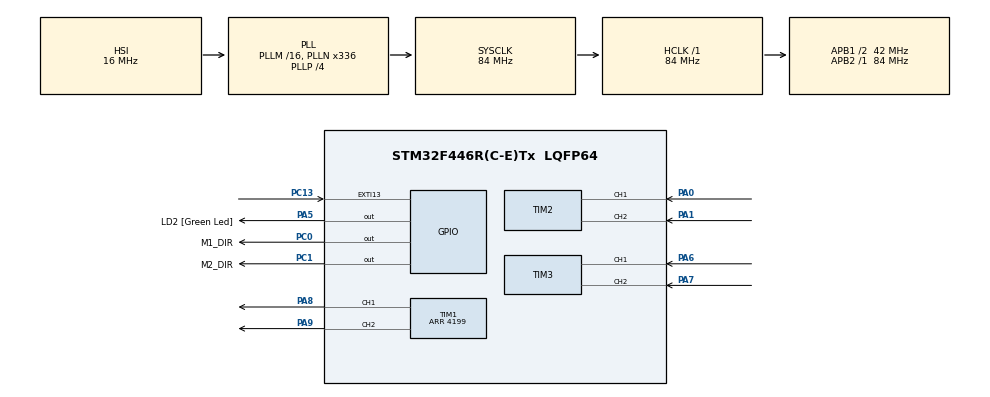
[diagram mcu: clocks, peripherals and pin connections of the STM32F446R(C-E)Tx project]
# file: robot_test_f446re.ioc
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Mcu.Family=STM32F4
Mcu.Name=STM32F446R(C-E)Tx
Mcu.Package=LQFP64
NUCLEO-F446RE.BUTTON=1
NVIC.EXTI15_10_IRQn=true\:0\:0\:false\:false\:true\:false\:true\:true
NVIC.PriorityGroup=NVIC_PRIORITYGROUP_0
PA0-WKUP.Signal=S_TIM2_CH1_ETR
PA1.Signal=S_TIM2_CH2
PA13.GPIO_Label=TMS
PA13.Signal=SYS_JTMS-SWDIO
PA14.GPIO_Label=TCK
PA14.Signal=SYS_JTCK-SWCLK
PA2.GPIO_Label=USART_TX
PA2.Signal=USART2_TX
PA3.GPIO_Label=USART_RX
PA3.Signal=USART2_RX
PA5.GPIO_Label=LD2 [Green Led]
PA5.Signal=GPIO_Output
PA6.Signal=S_TIM3_CH1
PA7.Signal=S_TIM3_CH2
PA8.Signal=S_TIM1_CH1
PA9.Signal=S_TIM1_CH2
PB3.GPIO_Label=SWO
PB3.Signal=SYS_JTDO-SWO
PC0.GPIO_Label=M1_DIR
PC0.Signal=GPIO_Output
PC1.GPIO_Label=M2_DIR
PC1.Signal=GPIO_Output
PC13.Signal=GPXTI13
PC14-OSC32_IN.Signal=RCC_OSC32_IN
PC15-OSC32_OUT.Signal=RCC_OSC32_OUT
PH0-OSC_IN.Signal=RCC_OSC_IN
PH1-OSC_OUT.Signal=RCC_OSC_OUT
ProjectManager.HeapSize=0x200
ProjectManager.StackSize=0x400
ProjectManager.TargetToolchain=STM32CubeIDE
RCC.AHBFreq_Value=84000000
RCC.APB1CLKDivider=RCC_HCLK_DIV2
RCC.APB1Freq_Value=42000000
RCC.APB1TimFreq_Value=84000000
RCC.APB2Freq_Value=84000000
RCC.APB2TimFreq_Value=84000000
RCC.CortexFreq_Value=84000000
RCC.FLatency-AdvancedSettings=FLASH_LATENCY_2
RCC.HCLKFreq_Value=84000000
RCC.HSE_VALUE=8000000
RCC.HSI_VALUE=16000000
RCC.LSE_VALUE=32768
RCC.PLLN=336
RCC.PLLP=RCC_PLLP_DIV4
RCC.SYSCLKFreq_VALUE=84000000
RCC.SYSCLKSource=RCC_SYSCLKSOURCE_PLLCLK
RCC.USBFreq_Value=168000000
RCC.VCOOutputFreq_Value=336000000
SH.S_TIM1_CH1.0=TIM1_CH1,PWM Generation1 CH1
SH.S_TIM1_CH2.0=TIM1_CH2,PWM Generation2 CH2
SH.S_TIM2_CH1_ETR.0=TIM2_CH1,Encoder_Interface
SH.S_TIM2_CH2.0=TIM2_CH2,Encoder_Interface
SH.S_TIM3_CH1.0=TIM3_CH1,Encoder_Interface
SH.S_TIM3_CH2.0=TIM3_CH2,Encoder_Interface
TIM1.AutoReloadPreload=TIM_AUTORELOAD_PRELOAD_ENABLE
TIM1.Channel-PWM\ Generation1\ CH1=TIM_CHANNEL_1
TIM1.Channel-PWM\ Generation2\ CH2=TIM_CHANNEL_2
TIM1.Period=4199
TIM2.EncoderMode=TIM_ENCODERMODE_TI12
TIM2.IC1Filter=4
TIM2.IC2Filter=4
TIM3.EncoderMode=TIM_ENCODERMODE_TI12
TIM3.IC1Filter=4
TIM3.IC2Filter=4
VP_NUCLEO-F446RE_VS_BSP_COMMON.Mode=COMMON
VP_TIM1_VS_ClockSourceINT.Mode=Internal
board=NUCLEO-F446RE

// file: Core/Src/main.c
/* USER CODE BEGIN Header */
/**
  ******************************************************************************
  * @file           : main.c
  * @brief          : Main program body
  ******************************************************************************
  * @attention
  *
  * Copyright (c) 2026 STMicroelectronics.
  * All rights reserved.
  *
  * This software is licensed under terms that can be found in the LICENSE file
  * in the root directory of this software component.
  * If no LICENSE file comes with this software, it is provided AS-IS.
  *
  ******************************************************************************
  */
/* USER CODE END Header */
#include "main.h"

/* USER CODE BEGIN Includes */
#include "motor_control.h"
#include "robot_link.h"
/* USER CODE END Includes */

TIM_HandleTypeDef htim1;
TIM_HandleTypeDef htim2;
TIM_HandleTypeDef htim3;

/* USER CODE BEGIN PV */
static IWDG_HandleTypeDef hiwdg;
/* USER CODE END PV */

void SystemClock_Config(void);
static void MX_GPIO_Init(void);
static void MX_TIM2_Init(void);
static void MX_TIM1_Init(void);
static void MX_TIM3_Init(void);

int main(void)
{

  /* MCU Configuration--------------------------------------------------------*/

  /* Reset of all peripherals, Initializes the Flash interface and the Systick. */
  HAL_Init();

  /* Configure the system clock */
  SystemClock_Config();

  /* Initialize all configured peripherals */
  MX_GPIO_Init();
  MX_TIM2_Init();
  MX_TIM1_Init();
  MX_TIM3_Init();
  /* USER CODE BEGIN 2 */
if (RobotLink_Init() != HAL_OK) Error_Handler();
if (Motor_Init() != HAL_OK) Error_Handler();
/* main 정지 시 약 1초(LSI 공차 있음) 후 MCU 리셋으로 PWM 차단. */
hiwdg.Instance = IWDG;
hiwdg.Init.Prescaler = IWDG_PRESCALER_64;
hiwdg.Init.Reload = 499;
if (HAL_IWDG_Init(&hiwdg) != HAL_OK) Error_Handler();
/* USER CODE END 2 */

  /* Initialize USER push-button, will be used to trigger an interrupt each time it's pressed.*/
  BSP_PB_Init(BUTTON_USER, BUTTON_MODE_EXTI);

  /* Infinite loop */
  while (1)
  {

    /* USER CODE BEGIN 3 */
    const uint32_t now = HAL_GetTick();
    RobotLink_Task(now);
    Motor_Update(now);
    if (HAL_IWDG_Refresh(&hiwdg) != HAL_OK) Error_Handler();
  }
/* USER CODE END 3 */
}

void SystemClock_Config(void)
{
  RCC_OscInitTypeDef RCC_OscInitStruct = {0};
  RCC_ClkInitTypeDef RCC_ClkInitStruct = {0};

  /** Configure the main internal regulator output voltage
  */
  __HAL_RCC_PWR_CLK_ENABLE();
  __HAL_PWR_VOLTAGESCALING_CONFIG(PWR_REGULATOR_VOLTAGE_SCALE3);

  /** Initializes the RCC Oscillators according to the specified parameters
  * in the RCC_OscInitTypeDef structure.
  */
  RCC_OscInitStruct.OscillatorType = RCC_OSCILLATORTYPE_HSI;
  RCC_OscInitStruct.HSIState = RCC_HSI_ON;
  RCC_OscInitStruct.HSICalibrationValue = RCC_HSICALIBRATION_DEFAULT;
  RCC_OscInitStruct.PLL.PLLState = RCC_PLL_ON;
  RCC_OscInitStruct.PLL.PLLSource = RCC_PLLSOURCE_HSI;
  RCC_OscInitStruct.PLL.PLLM = 16;
  RCC_OscInitStruct.PLL.PLLN = 336;
  RCC_OscInitStruct.PLL.PLLP = RCC_PLLP_DIV4;
  RCC_OscInitStruct.PLL.PLLQ = 2;
  RCC_OscInitStruct.PLL.PLLR = 2;
  if (HAL_RCC_OscConfig(&RCC_OscInitStruct) != HAL_OK)
  {
    Error_Handler();
  }

  /** Initializes the CPU, AHB and APB buses clocks
  */
  RCC_ClkInitStruct.ClockType = RCC_CLOCKTYPE_HCLK|RCC_CLOCKTYPE_SYSCLK
                              |RCC_CLOCKTYPE_PCLK1|RCC_CLOCKTYPE_PCLK2;
  RCC_ClkInitStruct.SYSCLKSource = RCC_SYSCLKSOURCE_PLLCLK;
  RCC_ClkInitStruct.AHBCLKDivider = RCC_SYSCLK_DIV1;
  RCC_ClkInitStruct.APB1CLKDivider = RCC_HCLK_DIV2;
  RCC_ClkInitStruct.APB2CLKDivider = RCC_HCLK_DIV1;

  if (HAL_RCC_ClockConfig(&RCC_ClkInitStruct, FLASH_LATENCY_2) != HAL_OK)
  {
    Error_Handler();
  }
}

static void MX_TIM1_Init(void)
{

  TIM_ClockConfigTypeDef sClockSourceConfig = {0};
  TIM_MasterConfigTypeDef sMasterConfig = {0};
  TIM_OC_InitTypeDef sConfigOC = {0};
  TIM_BreakDeadTimeConfigTypeDef sBreakDeadTimeConfig = {0};

  htim1.Instance = TIM1;
  htim1.Init.Prescaler = 0;
  htim1.Init.CounterMode = TIM_COUNTERMODE_UP;
  htim1.Init.Period = 4199;
  htim1.Init.ClockDivision = TIM_CLOCKDIVISION_DIV1;
  htim1.Init.RepetitionCounter = 0;
  htim1.Init.AutoReloadPreload = TIM_AUTORELOAD_PRELOAD_ENABLE;
  if (HAL_TIM_Base_Init(&htim1) != HAL_OK)
  {
    Error_Handler();
  }
  sClockSourceConfig.ClockSource = TIM_CLOCKSOURCE_INTERNAL;
  if (HAL_TIM_ConfigClockSource(&htim1, &sClockSourceConfig) != HAL_OK)
  {
    Error_Handler();
  }
  if (HAL_TIM_PWM_Init(&htim1) != HAL_OK)
  {
    Error_Handler();
  }
  sMasterConfig.MasterOutputTrigger = TIM_TRGO_RESET;
  sMasterConfig.MasterSlaveMode = TIM_MASTERSLAVEMODE_DISABLE;
  if (HAL_TIMEx_MasterConfigSynchronization(&htim1, &sMasterConfig) != HAL_OK)
  {
    Error_Handler();
  }
  sConfigOC.OCMode = TIM_OCMODE_PWM1;
  sConfigOC.Pulse = 0;
  sConfigOC.OCPolarity = TIM_OCPOLARITY_HIGH;
  sConfigOC.OCNPolarity = TIM_OCNPOLARITY_HIGH;
  sConfigOC.OCFastMode = TIM_OCFAST_DISABLE;
  sConfigOC.OCIdleState = TIM_OCIDLESTATE_RESET;
  sConfigOC.OCNIdleState = TIM_OCNIDLESTATE_RESET;
  if (HAL_TIM_PWM_ConfigChannel(&htim1, &sConfigOC, TIM_CHANNEL_1) != HAL_OK)
  {
    Error_Handler();
  }
  if (HAL_TIM_PWM_ConfigChannel(&htim1, &sConfigOC, TIM_CHANNEL_2) != HAL_OK)
  {
    Error_Handler();
  }
  sBreakDeadTimeConfig.OffStateRunMode = TIM_OSSR_DISABLE;
  sBreakDeadTimeConfig.OffStateIDLEMode = TIM_OSSI_DISABLE;
  sBreakDeadTimeConfig.LockLevel = TIM_LOCKLEVEL_OFF;
  sBreakDeadTimeConfig.DeadTime = 0;
  sBreakDeadTimeConfig.BreakState = TIM_BREAK_DISABLE;
  sBreakDeadTimeConfig.BreakPolarity = TIM_BREAKPOLARITY_HIGH;
  sBreakDeadTimeConfig.AutomaticOutput = TIM_AUTOMATICOUTPUT_DISABLE;
  if (HAL_TIMEx_ConfigBreakDeadTime(&htim1, &sBreakDeadTimeConfig) != HAL_OK)
  {
    Error_Handler();
  }
  HAL_TIM_MspPostInit(&htim1);

}

static void MX_TIM2_Init(void)
{

  TIM_Encoder_InitTypeDef sConfig = {0};
  TIM_MasterConfigTypeDef sMasterConfig = {0};

  htim2.Instance = TIM2;
  htim2.Init.Prescaler = 0;
  htim2.Init.CounterMode = TIM_COUNTERMODE_UP;
  htim2.Init.Period = 4294967295;
  htim2.Init.ClockDivision = TIM_CLOCKDIVISION_DIV1;
  htim2.Init.AutoReloadPreload = TIM_AUTORELOAD_PRELOAD_DISABLE;
  sConfig.EncoderMode = TIM_ENCODERMODE_TI12;
  sConfig.IC1Polarity = TIM_ICPOLARITY_RISING;
  sConfig.IC1Selection = TIM_ICSELECTION_DIRECTTI;
  sConfig.IC1Prescaler = TIM_ICPSC_DIV1;
  sConfig.IC1Filter = 4;
  sConfig.IC2Polarity = TIM_ICPOLARITY_RISING;
  sConfig.IC2Selection = TIM_ICSELECTION_DIRECTTI;
  sConfig.IC2Prescaler = TIM_ICPSC_DIV1;
  sConfig.IC2Filter = 4;
  if (HAL_TIM_Encoder_Init(&htim2, &sConfig) != HAL_OK)
  {
    Error_Handler();
  }
  sMasterConfig.MasterOutputTrigger = TIM_TRGO_RESET;
  sMasterConfig.MasterSlaveMode = TIM_MASTERSLAVEMODE_DISABLE;
  if (HAL_TIMEx_MasterConfigSynchronization(&htim2, &sMasterConfig) != HAL_OK)
  {
    Error_Handler();
  }

}

static void MX_TIM3_Init(void)
{

  TIM_Encoder_InitTypeDef sConfig = {0};
  TIM_MasterConfigTypeDef sMasterConfig = {0};

  htim3.Instance = TIM3;
  htim3.Init.Prescaler = 0;
  htim3.Init.CounterMode = TIM_COUNTERMODE_UP;
  htim3.Init.Period = 65535;
  htim3.Init.ClockDivision = TIM_CLOCKDIVISION_DIV1;
  htim3.Init.AutoReloadPreload = TIM_AUTORELOAD_PRELOAD_DISABLE;
  sConfig.EncoderMode = TIM_ENCODERMODE_TI12;
  sConfig.IC1Polarity = TIM_ICPOLARITY_RISING;
  sConfig.IC1Selection = TIM_ICSELECTION_DIRECTTI;
  sConfig.IC1Prescaler = TIM_ICPSC_DIV1;
  sConfig.IC1Filter = 4;
  sConfig.IC2Polarity = TIM_ICPOLARITY_RISING;
  sConfig.IC2Selection = TIM_ICSELECTION_DIRECTTI;
  sConfig.IC2Prescaler = TIM_ICPSC_DIV1;
  sConfig.IC2Filter = 4;
  if (HAL_TIM_Encoder_Init(&htim3, &sConfig) != HAL_OK)
  {
    Error_Handler();
  }
  sMasterConfig.MasterOutputTrigger = TIM_TRGO_RESET;
  sMasterConfig.MasterSlaveMode = TIM_MASTERSLAVEMODE_DISABLE;
  if (HAL_TIMEx_MasterConfigSynchronization(&htim3, &sMasterConfig) != HAL_OK)
  {
    Error_Handler();
  }

}

static void MX_GPIO_Init(void)
{
  GPIO_InitTypeDef GPIO_InitStruct = {0};

  /* GPIO Ports Clock Enable */
  __HAL_RCC_GPIOC_CLK_ENABLE();
  __HAL_RCC_GPIOH_CLK_ENABLE();
  __HAL_RCC_GPIOA_CLK_ENABLE();
  __HAL_RCC_GPIOB_CLK_ENABLE();

  /*Configure GPIO pin Output Level */
  HAL_GPIO_WritePin(GPIOC, M1_DIR_Pin|M2_DIR_Pin, GPIO_PIN_RESET);

  /*Configure GPIO pin Output Level */
  HAL_GPIO_WritePin(LD2_GPIO_Port, LD2_Pin, GPIO_PIN_RESET);

  /*Configure GPIO pins : M1_DIR_Pin M2_DIR_Pin */
  GPIO_InitStruct.Pin = M1_DIR_Pin|M2_DIR_Pin;
  GPIO_InitStruct.Mode = GPIO_MODE_OUTPUT_PP;
  GPIO_InitStruct.Pull = GPIO_NOPULL;
  GPIO_InitStruct.Speed = GPIO_SPEED_FREQ_LOW;
  HAL_GPIO_Init(GPIOC, &GPIO_InitStruct);

  /*Configure GPIO pins : USART_TX_Pin USART_RX_Pin */
  GPIO_InitStruct.Pin = USART_TX_Pin|USART_RX_Pin;
  GPIO_InitStruct.Mode = GPIO_MODE_AF_PP;
  GPIO_InitStruct.Pull = GPIO_NOPULL;
  GPIO_InitStruct.Speed = GPIO_SPEED_FREQ_VERY_HIGH;
  GPIO_InitStruct.Alternate = GPIO_AF7_USART2;
  HAL_GPIO_Init(GPIOA, &GPIO_InitStruct);

  /*Configure GPIO pin : LD2_Pin */
  GPIO_InitStruct.Pin = LD2_Pin;
  GPIO_InitStruct.Mode = GPIO_MODE_OUTPUT_PP;
  GPIO_InitStruct.Pull = GPIO_NOPULL;
  GPIO_InitStruct.Speed = GPIO_SPEED_FREQ_LOW;
  HAL_GPIO_Init(LD2_GPIO_Port, &GPIO_InitStruct);

}

void Error_Handler(void)
{
  /* USER CODE BEGIN Error_Handler_Debug */
Motor_EmergencyStop();
__disable_irq();
while (1) {}
/* USER CODE END Error_Handler_Debug */
}
